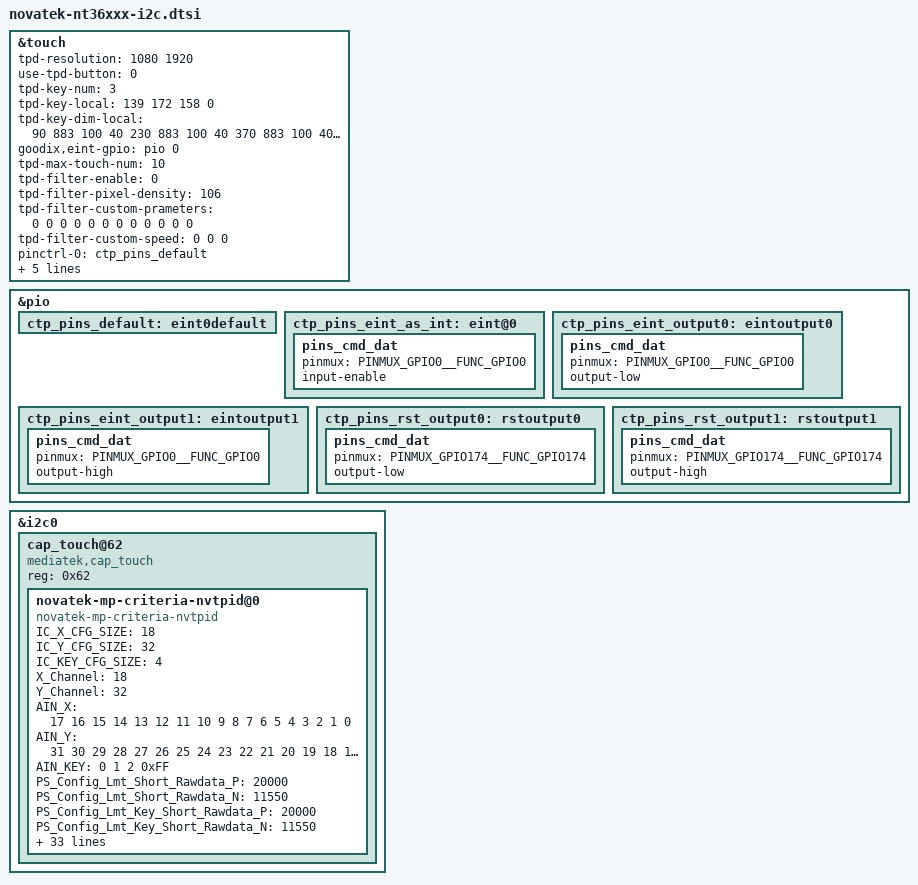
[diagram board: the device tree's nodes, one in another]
// SPDX-License-Identifier: GPL-2.0+
/*
 * Copyright (c) 2019 MediaTek Inc.
 *
 */

/* TOUCH start */
&touch {
	tpd-resolution = <1080 1920>;
	use-tpd-button = <0>;
	tpd-key-num = <3>;
	tpd-key-local= <139 172 158 0>;
	tpd-key-dim-local = <90 883 100 40 230
				 883 100 40 370 883 100 40 0 0 0 0>;
	goodix,eint-gpio = <&pio 0 0x0>;
	tpd-max-touch-num = <10>;
	tpd-filter-enable = <0>;
	tpd-filter-pixel-density = <106>;
	tpd-filter-custom-prameters = <0 0 0 0 0 0 0 0 0 0 0 0>;
	tpd-filter-custom-speed = <0 0 0>;
	pinctrl-names = "default", "state_eint_as_int", "state_eint_output0",
		"state_eint_output1", "state_rst_output0", "state_rst_output1";
	pinctrl-0 = <&ctp_pins_default>;
	pinctrl-1 = <&ctp_pins_eint_as_int>;
	pinctrl-2 = <&ctp_pins_eint_output0>;
	pinctrl-3 = <&ctp_pins_eint_output1>;
	pinctrl-4 = <&ctp_pins_rst_output0>;
	pinctrl-5 = <&ctp_pins_rst_output1>;
	status = "okay";
};

&pio {
	ctp_pins_default: eint0default {
	};
	ctp_pins_eint_as_int: eint@0 {
		pins_cmd_dat {
			pinmux = <PINMUX_GPIO0__FUNC_GPIO0>;
			input-enable;
		};
	};
	ctp_pins_eint_output0: eintoutput0 {
		pins_cmd_dat {
			pinmux = <PINMUX_GPIO0__FUNC_GPIO0>;
			output-low;
		};
	};
	ctp_pins_eint_output1: eintoutput1 {
		pins_cmd_dat {
			pinmux = <PINMUX_GPIO0__FUNC_GPIO0>;
			output-high;
		};
	};
	ctp_pins_rst_output0: rstoutput0 {
		pins_cmd_dat {
			pinmux = <PINMUX_GPIO174__FUNC_GPIO174>;
			output-low;
		};
	};
	ctp_pins_rst_output1: rstoutput1 {
		pins_cmd_dat {
			pinmux = <PINMUX_GPIO174__FUNC_GPIO174>;
			output-high;
		};
	};
};

&i2c0 {

	/* Novatek device tree node */
	cap_touch@62 {
	compatible = "mediatek,cap_touch";	//Use MTK default touch
	reg = <0x62>;
	status = "okay";

	/* MP */
	//novatek,mp-support-dt;

	novatek-mp-criteria-nvtpid@0 {
		#address-cells = <1>;
		#size-cells = <0>;
		compatible = "novatek-mp-criteria-nvtpid";

		/* MP Config */
		IC_X_CFG_SIZE = <18>;
		IC_Y_CFG_SIZE = <32>;
		IC_KEY_CFG_SIZE = <4>;
		X_Channel = <18>;
		Y_Channel = <32>;
		AIN_X = <17 16 15 14 13 12 11 10 9 8 7 6 5 4 3 2 1 0>;
		AIN_Y = <31 30 29 28 27 26 25 24 23 22 21 20 19 18 17 16 15
		14 13 12 11 10 9 8 7 6 5 4 3 2 1 0>;
		AIN_KEY = <0 1 2 0xFF>;

		/* MP Criteria */
		PS_Config_Lmt_Short_Rawdata_P = <20000>;
		PS_Config_Lmt_Short_Rawdata_N = <11550>;
		PS_Config_Lmt_Key_Short_Rawdata_P = <20000>;
		PS_Config_Lmt_Key_Short_Rawdata_N = <11550>;
		PS_Config_Lmt_Short_Diff_P = <6300>;
		PS_Config_Lmt_Short_Diff_N = <0>;
		PS_Config_Lmt_Key_Short_Diff_P = <6300>;
		PS_Config_Lmt_Key_Short_Diff_N = <0>;
		PS_Config_Lmt_Short_Base_P = <2000>;
		PS_Config_Lmt_Short_Base_N = <(-2000)>;
		PS_Config_Lmt_Key_Short_Base_P = <2000>;
		PS_Config_Lmt_Key_Short_Base_N = <(-2000)>;

		PS_Config_Lmt_Open_Rawdata_P = <
			13000 13000 13000 13000 13000 13000 13000 13000 13000
			13000 13000 13000 13000 13000 13000 13000 13000 13000
			13000 13000 13000 13000 13000 13000 13000 13000 13000
			13000 13000 13000 13000 13000 13000 13000 13000 13000
			13000 13000 13000 13000 13000 13000 13000 13000 13000
			13000 13000 13000 13000 13000 13000 13000 13000 13000
			13000 13000 13000 13000 13000 13000 13000 13000 13000
			13000 13000 13000 13000 13000 13000 13000 13000 13000
			13000 13000 13000 13000 13000 13000 13000 13000 13000
			13000 13000 13000 13000 13000 13000 13000 13000 13000
			13000 13000 13000 13000 13000 13000 13000 13000 13000
			13000 13000 13000 13000 13000 13000 13000 13000 13000
			13000 13000 13000 13000 13000 13000 13000 13000 13000
			13000 13000 13000 13000 13000 13000 13000 13000 13000
			13000 13000 13000 13000 13000 13000 13000 13000 13000
			13000 13000 13000 13000 13000 13000 13000 13000 13000
			13000 13000 13000 13000 13000 13000 13000 13000 13000
			13000 13000 13000 13000 13000 13000 13000 13000 13000
			13000 13000 13000 13000 13000 13000 13000 13000 13000
			13000 13000 13000 13000 13000 13000 13000 13000 13000
			13000 13000 13000 13000 13000 13000 13000 13000 13000
			13000 13000 13000 13000 13000 13000 13000 13000 13000
			13000 13000 13000 13000 13000 13000 13000 13000 13000
			13000 13000 13000 13000 13000 13000 13000 13000 13000
			13000 13000 13000 13000 13000 13000 13000 13000 13000
			13000 13000 13000 13000 13000 13000 13000 13000 13000
			13000 13000 13000 13000 13000 13000 13000 13000 13000
			13000 13000 13000 13000 13000 13000 13000 13000 13000
			13000 13000 13000 13000 13000 13000 13000 13000 13000
			13000 13000 13000 13000 13000 13000 13000 13000 13000
			13000 13000 13000 13000 13000 13000 13000 13000 13000
			13000 13000 13000 13000 13000 13000 13000 13000 13000
			13000 13000 13000 13000 13000 13000 13000 13000 13000
			13000 13000 13000 13000 13000 13000 13000 13000 13000
			13000 13000 13000 13000 13000 13000 13000 13000 13000
			13000 13000 13000 13000 13000 13000 13000 13000 13000
			13000 13000 13000 13000 13000 13000 13000 13000 13000
			13000 13000 13000 13000 13000 13000 13000 13000 13000
			13000 13000 13000 13000 13000 13000 13000 13000 13000
			13000 13000 13000 13000 13000 13000 13000 13000 13000
			13000 13000 13000 13000 13000 13000 13000 13000 13000
			13000 13000 13000 13000 13000 13000 13000 13000 13000
			13000 13000 13000 13000 13000 13000 13000 13000 13000
			13000 13000 13000 13000 13000 13000 13000 13000 13000
			13000 13000 13000 13000 13000 13000 13000 13000 13000
			13000 13000 13000 13000 13000 13000 13000 13000 13000
			13000 13000 13000 13000 13000 13000 13000 13000 13000
			13000 13000 13000 13000 13000 13000 13000 13000 13000
			13000 13000 13000 13000 13000 13000 13000 13000 13000
			13000 13000 13000 13000 13000 13000 13000 13000 13000
			13000 13000 13000 13000 13000 13000 13000 13000 13000
			13000 13000 13000 13000 13000 13000 13000 13000 13000
			13000 13000 13000 13000 13000 13000 13000 13000 13000
			13000 13000 13000 13000 13000 13000 13000 13000 13000
			13000 13000 13000 13000 13000 13000 13000 13000 13000
			13000 13000 13000 13000 13000 13000 13000 13000 13000
			13000 13000 13000 13000 13000 13000 13000 13000 13000
			13000 13000 13000 13000 13000 13000 13000 13000 13000
			13000 13000 13000 13000 13000 13000 13000 13000 13000
			13000 13000 13000 13000 13000 13000 13000 13000 13000
			13000 13000 13000 13000 13000 13000 13000 13000 13000
			13000 13000 13000 13000 13000 13000 13000 13000 13000
			13000 13000 13000 13000 13000 13000 13000 13000 13000
			13000 13000 13000 13000 13000 13000 13000 13000 13000
			13000 13000 13000>;

		PS_Config_Lmt_Open_Rawdata_N = <
			6500 6500 6500 6500 6500 6500 6500 6500 6500
			6500 6500 6500 6500 6500 6500 6500 6500 6500
			6500 6500 6500 6500 6500 6500 6500 6500 6500
			6500 6500 6500 6500 6500 6500 6500 6500 6500
			6500 6500 6500 6500 6500 6500 6500 6500 6500
			6500 6500 6500 6500 6500 6500 6500 6500 6500
			6500 6500 6500 6500 6500 6500 6500 6500 6500
			6500 6500 6500 6500 6500 6500 6500 6500 6500
			6500 6500 6500 6500 6500 6500 6500 6500 6500
			6500 6500 6500 6500 6500 6500 6500 6500 6500
			6500 6500 6500 6500 6500 6500 6500 6500 6500
			6500 6500 6500 6500 6500 6500 6500 6500 6500
			6500 6500 6500 6500 6500 6500 6500 6500 6500
			6500 6500 6500 6500 6500 6500 6500 6500 6500
			6500 6500 6500 6500 6500 6500 6500 6500 6500
			6500 6500 6500 6500 6500 6500 6500 6500 6500
			6500 6500 6500 6500 6500 6500 6500 6500 6500
			6500 6500 6500 6500 6500 6500 6500 6500 6500
			6500 6500 6500 6500 6500 6500 6500 6500 6500
			6500 6500 6500 6500 6500 6500 6500 6500 6500
			6500 6500 6500 6500 6500 6500 6500 6500 6500
			6500 6500 6500 6500 6500 6500 6500 6500 6500
			6500 6500 6500 6500 6500 6500 6500 6500 6500
			6500 6500 6500 6500 6500 6500 6500 6500 6500
			6500 6500 6500 6500 6500 6500 6500 6500 6500
			6500 6500 6500 6500 6500 6500 6500 6500 6500
			6500 6500 6500 6500 6500 6500 6500 6500 6500
			6500 6500 6500 6500 6500 6500 6500 6500 6500
			6500 6500 6500 6500 6500 6500 6500 6500 6500
			6500 6500 6500 6500 6500 6500 6500 6500 6500
			6500 6500 6500 6500 6500 6500 6500 6500 6500
			6500 6500 6500 6500 6500 6500 6500 6500 6500
			6500 6500 6500 6500 6500 6500 6500 6500 6500
			6500 6500 6500 6500 6500 6500 6500 6500 6500
			6500 6500 6500 6500 6500 6500 6500 6500 6500
			6500 6500 6500 6500 6500 6500 6500 6500 6500
			6500 6500 6500 6500 6500 6500 6500 6500 6500
			6500 6500 6500 6500 6500 6500 6500 6500 6500
			6500 6500 6500 6500 6500 6500 6500 6500 6500
			6500 6500 6500 6500 6500 6500 6500 6500 6500
			6500 6500 6500 6500 6500 6500 6500 6500 6500
			6500 6500 6500 6500 6500 6500 6500 6500 6500
			6500 6500 6500 6500 6500 6500 6500 6500 6500
			6500 6500 6500 6500 6500 6500 6500 6500 6500
			6500 6500 6500 6500 6500 6500 6500 6500 6500
			6500 6500 6500 6500 6500 6500 6500 6500 6500
			6500 6500 6500 6500 6500 6500 6500 6500 6500
			6500 6500 6500 6500 6500 6500 6500 6500 6500
			6500 6500 6500 6500 6500 6500 6500 6500 6500
			6500 6500 6500 6500 6500 6500 6500 6500 6500
			6500 6500 6500 6500 6500 6500 6500 6500 6500
			6500 6500 6500 6500 6500 6500 6500 6500 6500
			6500 6500 6500 6500 6500 6500 6500 6500 6500
			6500 6500 6500 6500 6500 6500 6500 6500 6500
			6500 6500 6500 6500 6500 6500 6500 6500 6500
			6500 6500 6500 6500 6500 6500 6500 6500 6500
			6500 6500 6500 6500 6500 6500 6500 6500 6500
			6500 6500 6500 6500 6500 6500 6500 6500 6500
			6500 6500 6500 6500 6500 6500 6500 6500 6500
			6500 6500 6500 6500 6500 6500 6500 6500 6500
			6500 6500 6500 6500 6500 6500 6500 6500 6500
			6500 6500 6500 6500 6500 6500 6500 6500 6500
			6500 6500 6500 6500 6500 6500 6500 6500 6500
			6500 6500 6500 6500 6500 6500 6500 6500 6500
			6500 6500 6500>;

		PS_Config_Lmt_FW_Rawdata_P = <
			2000 2000 2000 2000 2000 2000 2000 2000 2000
			2000 2000 2000 2000 2000 2000 2000 2000 2000
			2000 2000 2000 2000 2000 2000 2000 2000 2000
			2000 2000 2000 2000 2000 2000 2000 2000 2000
			2000 2000 2000 2000 2000 2000 2000 2000 2000
			2000 2000 2000 2000 2000 2000 2000 2000 2000
			2000 2000 2000 2000 2000 2000 2000 2000 2000
			2000 2000 2000 2000 2000 2000 2000 2000 2000
			2000 2000 2000 2000 2000 2000 2000 2000 2000
			2000 2000 2000 2000 2000 2000 2000 2000 2000
			2000 2000 2000 2000 2000 2000 2000 2000 2000
			2000 2000 2000 2000 2000 2000 2000 2000 2000
			2000 2000 2000 2000 2000 2000 2000 2000 2000
			2000 2000 2000 2000 2000 2000 2000 2000 2000
			2000 2000 2000 2000 2000 2000 2000 2000 2000
			2000 2000 2000 2000 2000 2000 2000 2000 2000
			2000 2000 2000 2000 2000 2000 2000 2000 2000
			2000 2000 2000 2000 2000 2000 2000 2000 2000
			2000 2000 2000 2000 2000 2000 2000 2000 2000
			2000 2000 2000 2000 2000 2000 2000 2000 2000
			2000 2000 2000 2000 2000 2000 2000 2000 2000
			2000 2000 2000 2000 2000 2000 2000 2000 2000
			2000 2000 2000 2000 2000 2000 2000 2000 2000
			2000 2000 2000 2000 2000 2000 2000 2000 2000
			2000 2000 2000 2000 2000 2000 2000 2000 2000
			2000 2000 2000 2000 2000 2000 2000 2000 2000
			2000 2000 2000 2000 2000 2000 2000 2000 2000
			2000 2000 2000 2000 2000 2000 2000 2000 2000
			2000 2000 2000 2000 2000 2000 2000 2000 2000
			2000 2000 2000 2000 2000 2000 2000 2000 2000
			2000 2000 2000 2000 2000 2000 2000 2000 2000
			2000 2000 2000 2000 2000 2000 2000 2000 2000
			2000 2000 2000 2000 2000 2000 2000 2000 2000
			2000 2000 2000 2000 2000 2000 2000 2000 2000
			2000 2000 2000 2000 2000 2000 2000 2000 2000
			2000 2000 2000 2000 2000 2000 2000 2000 2000
			2000 2000 2000 2000 2000 2000 2000 2000 2000
			2000 2000 2000 2000 2000 2000 2000 2000 2000
			2000 2000 2000 2000 2000 2000 2000 2000 2000
			2000 2000 2000 2000 2000 2000 2000 2000 2000
			2000 2000 2000 2000 2000 2000 2000 2000 2000
			2000 2000 2000 2000 2000 2000 2000 2000 2000
			2000 2000 2000 2000 2000 2000 2000 2000 2000
			2000 2000 2000 2000 2000 2000 2000 2000 2000
			2000 2000 2000 2000 2000 2000 2000 2000 2000
			2000 2000 2000 2000 2000 2000 2000 2000 2000
			2000 2000 2000 2000 2000 2000 2000 2000 2000
			2000 2000 2000 2000 2000 2000 2000 2000 2000
			2000 2000 2000 2000 2000 2000 2000 2000 2000
			2000 2000 2000 2000 2000 2000 2000 2000 2000
			2000 2000 2000 2000 2000 2000 2000 2000 2000
			2000 2000 2000 2000 2000 2000 2000 2000 2000
			2000 2000 2000 2000 2000 2000 2000 2000 2000
			2000 2000 2000 2000 2000 2000 2000 2000 2000
			2000 2000 2000 2000 2000 2000 2000 2000 2000
			2000 2000 2000 2000 2000 2000 2000 2000 2000
			2000 2000 2000 2000 2000 2000 2000 2000 2000
			2000 2000 2000 2000 2000 2000 2000 2000 2000
			2000 2000 2000 2000 2000 2000 2000 2000 2000
			2000 2000 2000 2000 2000 2000 2000 2000 2000
			2000 2000 2000 2000 2000 2000 2000 2000 2000
			2000 2000 2000 2000 2000 2000 2000 2000 2000
			2000 2000 2000 2000 2000 2000 2000 2000 2000
			2000 2000 2000 2000 2000 2000 2000 2000 2000
			2000 2000 2000>;

		PS_Config_Lmt_FW_Rawdata_N= <
			400 400 400 400 400 400 400 400 400
			400 400 400 400 400 400 400 400 400
			400 400 400 400 400 400 400 400 400
			400 400 400 400 400 400 400 400 400
			400 400 400 400 400 400 400 400 400
			400 400 400 400 400 400 400 400 400
			400 400 400 400 400 400 400 400 400
			400 400 400 400 400 400 400 400 400
			400 400 400 400 400 400 400 400 400
			400 400 400 400 400 400 400 400 400
			400 400 400 400 400 400 400 400 400
			400 400 400 400 400 400 400 400 400
			400 400 400 400 400 400 400 400 400
			400 400 400 400 400 400 400 400 400
			400 400 400 400 400 400 400 400 400
			400 400 400 400 400 400 400 400 400
			400 400 400 400 400 400 400 400 400
			400 400 400 400 400 400 400 400 400
			400 400 400 400 400 400 400 400 400
			400 400 400 400 400 400 400 400 400
			400 400 400 400 400 400 400 400 400
			400 400 400 400 400 400 400 400 400
			400 400 400 400 400 400 400 400 400
			400 400 400 400 400 400 400 400 400
			400 400 400 400 400 400 400 400 400
			400 400 400 400 400 400 400 400 400
			400 400 400 400 400 400 400 400 400
			400 400 400 400 400 400 400 400 400
			400 400 400 400 400 400 400 400 400
			400 400 400 400 400 400 400 400 400
			400 400 400 400 400 400 400 400 400
			400 400 400 400 400 400 400 400 400
			400 400 400 400 400 400 400 400 400
			400 400 400 400 400 400 400 400 400
			400 400 400 400 400 400 400 400 400
			400 400 400 400 400 400 400 400 400
			400 400 400 400 400 400 400 400 400
			400 400 400 400 400 400 400 400 400
			400 400 400 400 400 400 400 400 400
			400 400 400 400 400 400 400 400 400
			400 400 400 400 400 400 400 400 400
			400 400 400 400 400 400 400 400 400
			400 400 400 400 400 400 400 400 400
			400 400 400 400 400 400 400 400 400
			400 400 400 400 400 400 400 400 400
			400 400 400 400 400 400 400 400 400
			400 400 400 400 400 400 400 400 400
			400 400 400 400 400 400 400 400 400
			400 400 400 400 400 400 400 400 400
			400 400 400 400 400 400 400 400 400
			400 400 400 400 400 400 400 400 400
			400 400 400 400 400 400 400 400 400
			400 400 400 400 400 400 400 400 400
			400 400 400 400 400 400 400 400 400
			400 400 400 400 400 400 400 400 400
			400 400 400 400 400 400 400 400 400
			400 400 400 400 400 400 400 400 400
			400 400 400 400 400 400 400 400 400
			400 400 400 400 400 400 400 400 400
			400 400 400 400 400 400 400 400 400
			400 400 400 400 400 400 400 400 400
			400 400 400 400 400 400 400 400 400
			400 400 400 400 400 400 400 400 400
			400 400 400 400 400 400 400 400 400
			400 400 400>;

		PS_Config_Lmt_FW_CC_P = <38>;
		PS_Config_Lmt_FW_CC_N = <9>;
		PS_Config_Lmt_Key_FW_CC_P = <38>;
		PS_Config_Lmt_Key_FW_CC_N = <9>;

		PS_Config_Lmt_FW_CC_I_P = <25>;
		PS_Config_Lmt_FW_CC_I_N = <0>;
		PS_Config_Lmt_FW_CC_Q_P = <25>;
		PS_Config_Lmt_FW_CC_Q_N = <0>;
		PS_Config_Lmt_Key_FW_CC_I_P = <25>;
		PS_Config_Lmt_Key_FW_CC_I_N = <0>;
		PS_Config_Lmt_Key_FW_CC_Q_P = <25>;
		PS_Config_Lmt_Key_FW_CC_Q_N = <0>;

		PS_Config_Lmt_FW_Diff_P = <35>;
		PS_Config_Lmt_FW_Diff_N = <(-35)>;
		PS_Config_Lmt_Key_FW_Diff_P = <35>;
		PS_Config_Lmt_Key_FW_Diff_N = <(-35)>;

		PS_Config_Diff_Test_Frame = <50>;
		};
	};
};
/* TOUCH end */
